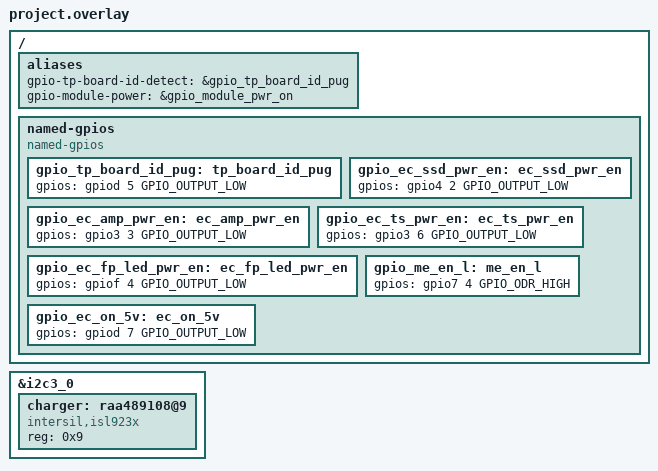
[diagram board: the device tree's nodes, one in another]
/* Copyright 2025 The ChromiumOS Authors
 * Use of this source code is governed by a BSD-style license that can be
 * found in the LICENSE file.
 */

#include "../marigold/adc.dtsi"
#include "../marigold/battery.dtsi"
#include "../marigold/fan.dtsi"
#include "../marigold/gpio.dtsi"
#include "../marigold/i2c.dtsi"
#include "../marigold/interrupts.dtsi"
#include "../marigold/keyboard.dtsi"
#include "../marigold/led_pins.dtsi"
#include "../marigold/led_policy.dtsi"
#include "../marigold/overlay.dtsi"
#include "../marigold/power_signal.dtsi"


/ {
	aliases {
		/delete-property/ gpio-mux-uart-flip;
		gpio-tp-board-id-detect = &gpio_tp_board_id_pug;
		gpio-module-power = &gpio_module_pwr_on;
	};

	named-gpios {
		compatible = "named-gpios";
		/delete-node/ mux_sub_uart_flip;
		/delete-node/ ec_beep;
		/delete-node/ power_vr_id;
		/delete-node/ me_en;
		/delete-node/ unused-pins;

		gpio_tp_board_id_pug: tp_board_id_pug {
			gpios = <&gpiod 5 GPIO_OUTPUT_LOW>;
		};

		gpio_ec_ssd_pwr_en: ec_ssd_pwr_en {
			gpios = <&gpio4 2 GPIO_OUTPUT_LOW>;
		};
		gpio_ec_amp_pwr_en: ec_amp_pwr_en {
			gpios = <&gpio3 3 GPIO_OUTPUT_LOW>;
		};
		gpio_ec_ts_pwr_en: ec_ts_pwr_en {
			gpios = <&gpio3 6 GPIO_OUTPUT_LOW>;
		};
		gpio_ec_fp_led_pwr_en: ec_fp_led_pwr_en {
			gpios = <&gpiof 4 GPIO_OUTPUT_LOW>;
		};
		gpio_me_en_l: me_en_l {
			gpios = <&gpio7 4 GPIO_ODR_HIGH>;
		};
		gpio_ec_on_5v: ec_on_5v {
			gpios = <&gpiod 7 GPIO_OUTPUT_LOW>; /* Reserved */
		};
	};
};

&i2c3_0 {
	/delete-node/ isl9241@9;

	charger: raa489108@9 {
		compatible = "intersil,isl923x";
		status = "okay";
		reg = <0x9>;
	};
};
